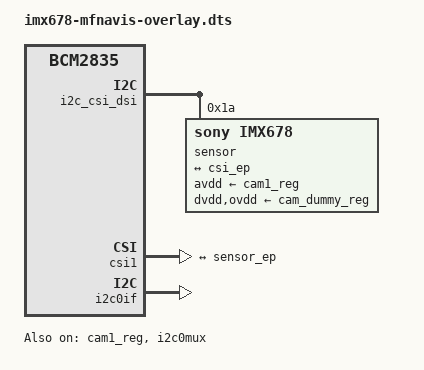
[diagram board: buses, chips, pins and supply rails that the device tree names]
// SPDX-License-Identifier: GPL-2.0-only
// MFNavis Pi adapter for the unmodified Linux upstream IMX678 driver.
// Default: CAM1, two lanes, 24 MHz XCLK, 891 Mbit/s/lane.
/dts-v1/;
/plugin/;

/ {
    compatible = "brcm,bcm2835";

    i2c_frag: fragment@0 {
        target = <&i2c_csi_dsi>;
        __overlay__ {
            status = "okay";
            #address-cells = <1>;
            #size-cells = <0>;
            sensor: imx678@1a {
                // Upstream's generic match reads the colour/mono ID register.
                compatible = "sony,imx678";
                reg = <0x1a>;
                clocks = <&cam1_clk>;
                avdd-supply = <&cam1_reg>;
                dvdd-supply = <&cam_dummy_reg>;
                ovdd-supply = <&cam_dummy_reg>;
                rotation = <0>;
                orientation = <0>;
                port {
                    sensor_ep: endpoint {
                        remote-endpoint = <&csi_ep>;
                        clock-lanes = <0>;
                        data-lanes = <1 2>;
                        link-frequencies = /bits/ 64 <445500000>;
                    };
                };
            };
        };
    };
    csi_frag: fragment@1 {
        target = <&csi1>;
        __overlay__ {
            status = "okay";
            brcm,media-controller;
            port {
                csi_ep: endpoint {
                    remote-endpoint = <&sensor_ep>;
                    data-lanes = <1 2>;
                };
            };
        };
    };
    clk_frag: fragment@2 {
        target = <&cam1_clk>;
        sensor_clk: __overlay__ {
            status = "okay";
            clock-frequency = <24000000>;
        };
    };
    reg_frag: fragment@3 {
        target = <&cam1_reg>;
        __overlay__ {
            status = "okay";
            startup-delay-us = <300000>;
        };
    };
    fragment@4 {
        target = <&i2c0if>;
        __overlay__ { status = "okay"; };
    };
    fragment@5 {
        target = <&i2c0mux>;
        __overlay__ { status = "okay"; };
    };
    fragment@6 {
        target = <&sensor_ep>;
        __dormant__ { data-lanes = <1 2 3 4>; };
    };
    fragment@7 {
        target = <&csi_ep>;
        __dormant__ { data-lanes = <1 2 3 4>; };
    };
    __overrides__ {
        cam0 = <&i2c_frag>, "target:0=", <&i2c_csi_dsi0>,
               <&csi_frag>, "target:0=", <&csi0>,
               <&clk_frag>, "target:0=", <&cam0_clk>,
               <&sensor>, "clocks:0=", <&cam0_clk>,
               <&reg_frag>, "target:0=", <&cam0_reg>,
               <&sensor>, "avdd-supply:0=", <&cam0_reg>;
        4lane = <0>, "+6+7";
        clock-frequency = <&sensor_clk>, "clock-frequency:0";
        link-frequency = <&sensor_ep>, "link-frequencies#0";
        rotation = <&sensor>, "rotation:0";
        orientation = <&sensor>, "orientation:0";
    };
};
